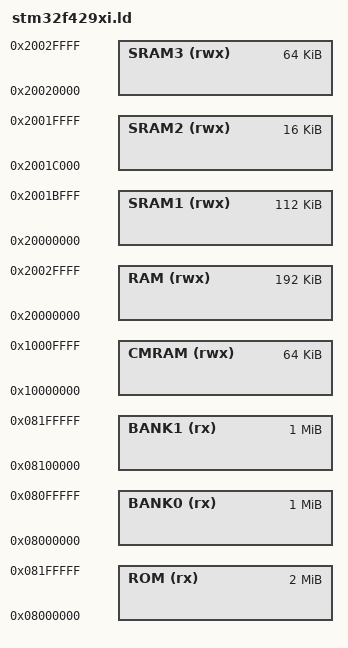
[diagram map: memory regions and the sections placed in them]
ENTRY(Reset_Handler)
MEMORY
{
    ROM    (rx): ORIGIN = 0x08000000, LENGTH = 2048K
    BANK0  (rx): ORIGIN = 0x08000000, LENGTH = 1024K
    BANK1  (rx): ORIGIN = 0x08100000, LENGTH = 1024K
    RAM   (rwx): ORIGIN = 0x20000000, LENGTH = 192K
    SRAM1 (rwx): ORIGIN = 0x20000000, LENGTH = 112K
    SRAM2 (rwx): ORIGIN = 0x2001C000, LENGTH = 16K
    SRAM3 (rwx): ORIGIN = 0x20020000, LENGTH = 64K
    CMRAM (rwx): ORIGIN = 0x10000000, LENGTH = 64K
}

INCLUDE sections.ld
